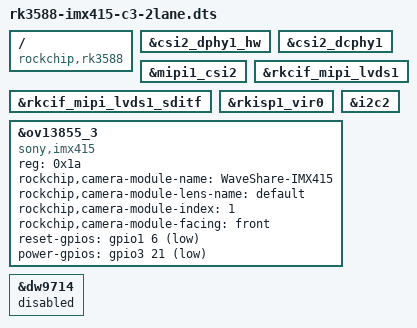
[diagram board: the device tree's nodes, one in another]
/dts-v1/;
/plugin/;


/ {
    compatible = "rockchip,rk3588";

    fragment@0 {
        target = <&csi2_dphy1_hw>;
        __overlay__ {
            status = "okay";
        };
    };

    fragment@1 {
        target = <&csi2_dcphy1>;
        __overlay__ {
            status = "okay";
        };
    };

    fragment@2 {
        target = <&mipi1_csi2>;
        __overlay__ {
            status = "okay";
        };
    };

    fragment@3 {
        target = <&rkcif_mipi_lvds1>;
        __overlay__ {
            status = "okay";
        };
    };

    fragment@4 {
        target = <&rkcif_mipi_lvds1_sditf>;
        __overlay__ {
            status = "okay";
        };
    };

    fragment@5 {
        target = <&rkisp1_vir0>;
        __overlay__ {
            status = "okay";
        };
    };

    fragment@6 {
        target = <&i2c2>;
        __overlay__ {
            status = "okay";
        };
    };

    fragment@7 {
        target = <&ov13855_3>;
        __overlay__ {
            status = "okay";
            compatible = "sony,imx415";
            reg = <0x1a>;
            rockchip,camera-module-name = "WaveShare-IMX415";
            rockchip,camera-module-lens-name = "default";
            rockchip,camera-module-index = <1>;
            rockchip,camera-module-facing = "front";
            reset-gpios = <&gpio1 6 1>;
            power-gpios = <&gpio3 21 1>;
            /delete-property/ lens-focus;
        };
    };

    fragment@8 {
        target = <&dw9714>;
        __overlay__ {
            status = "disabled";
        };
    };
};
